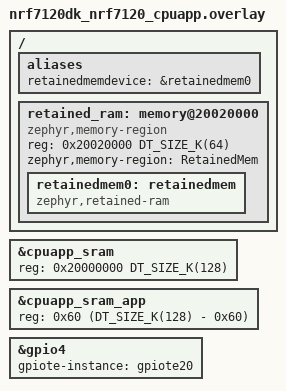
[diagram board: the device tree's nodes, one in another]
/*
 * Copyright (c) 2026 Nordic Semiconductor ASA
 *
 * SPDX-License-Identifier: LicenseRef-Nordic-5-Clause
 */

/ {
	aliases {
		retainedmemdevice = &retainedmem0;
	};

	retained_ram: memory@20020000 {
		compatible = "zephyr,memory-region", "mmio-sram";
		reg = <0x20020000 DT_SIZE_K(64)>;
		zephyr,memory-region = "RetainedMem";
		status = "okay";

		retainedmem0: retainedmem {
			compatible = "zephyr,retained-ram";
			status = "okay";
		};
	};
};

&cpuapp_sram {
	/* Reserve two aligned 32 KiB sections for the retention test. */
	reg = <0x20000000 DT_SIZE_K(128)>;
	ranges = <0x0 0x20000000 DT_SIZE_K(128)>;
};

&cpuapp_sram_app {
	reg = <0x60 (DT_SIZE_K(128) - 0x60)>;
};

&gpio4 {
	gpiote-instance = <&gpiote20>;
};
